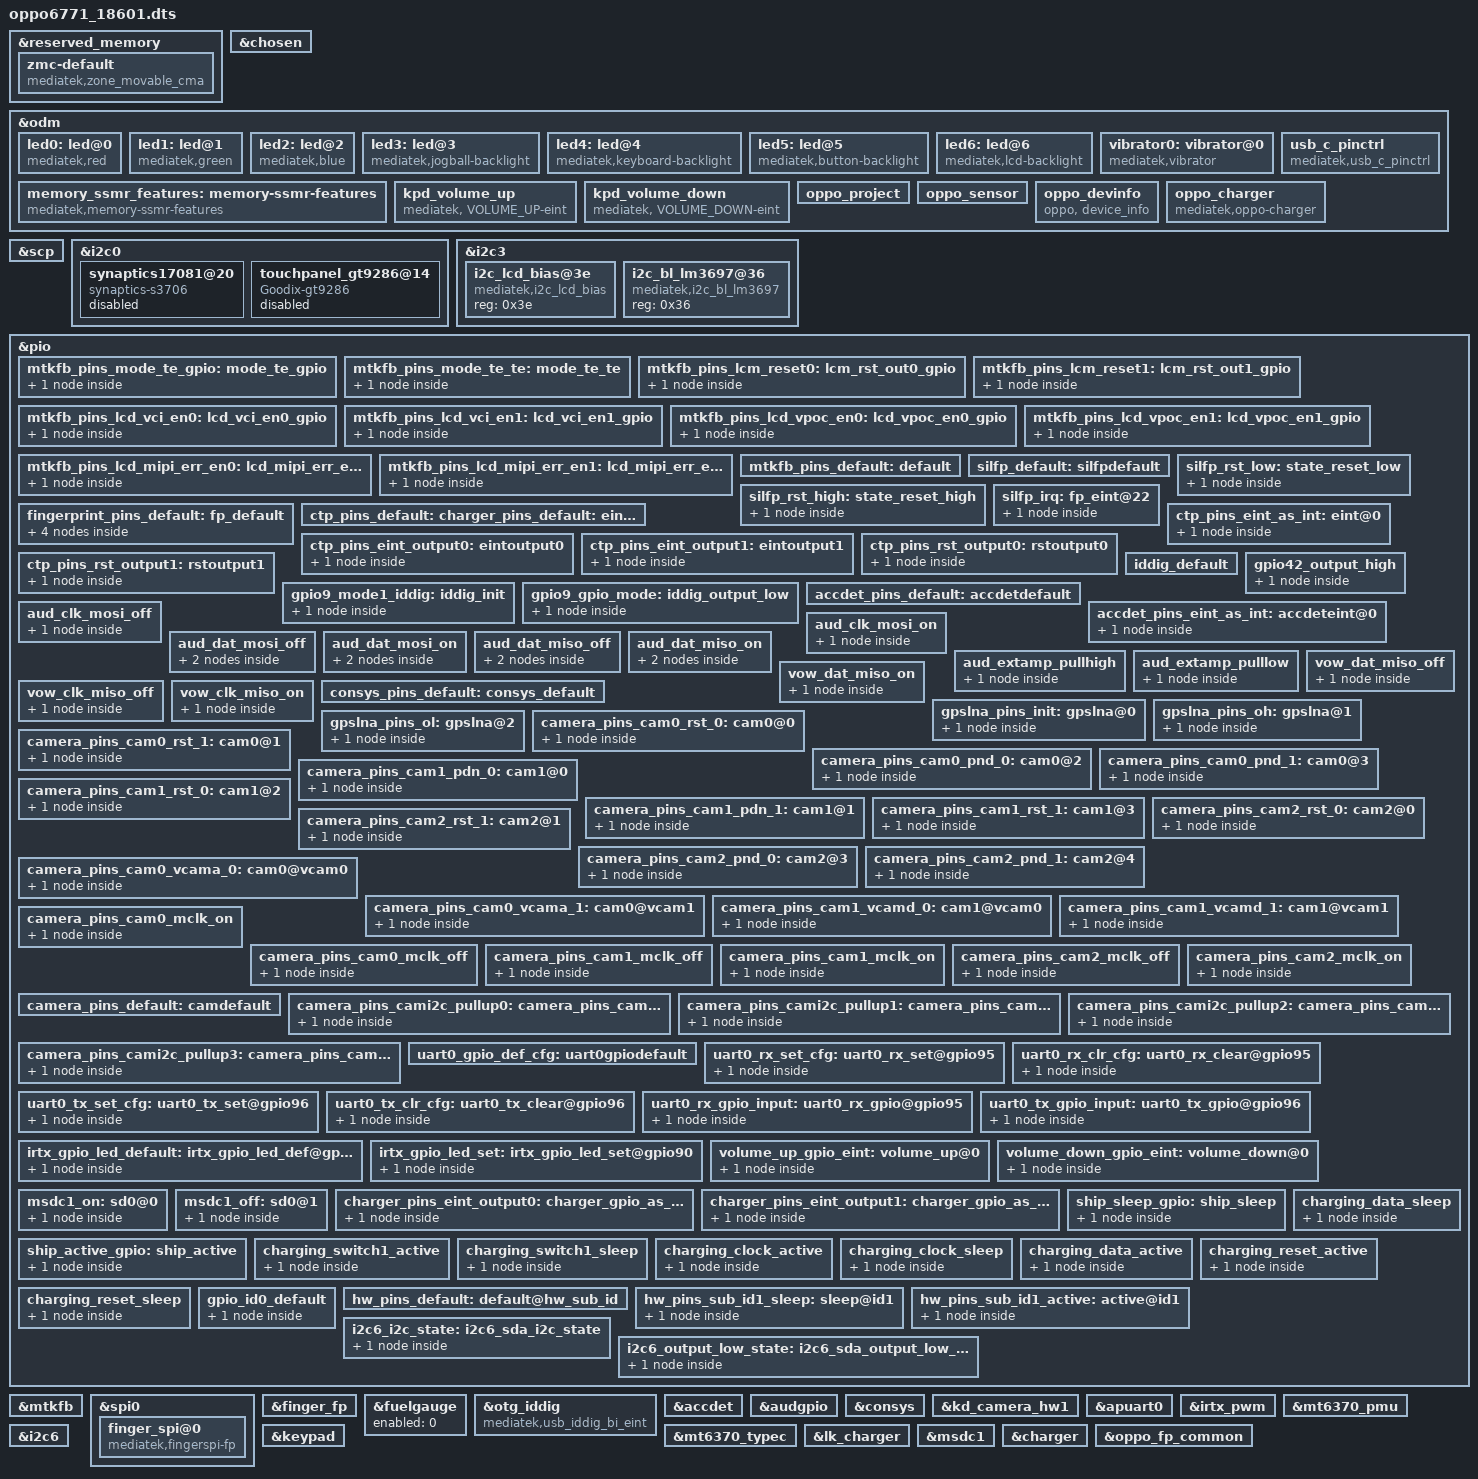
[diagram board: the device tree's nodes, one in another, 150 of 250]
/dts-v1/;
/plugin/;
#include <dt-bindings/interrupt-controller/irq.h>
#include <dt-bindings/interrupt-controller/arm-gic.h>
#include <dt-bindings/pinctrl/mt6771-pinfunc.h>
/* #ifdef ODM_HQ_EDIT */
/* liyan@ODM_HQ.BSP.MMC 2018/10/09 add for T-card irq level */
#include <dt-bindings/mmc/mt6771-msdc.h>
/* #endif */

&reserved_memory {
	#address-cells = <2>;
	#size-cells = <2>;
	ranges;

	zmc-default {
		compatible = "mediatek,zone_movable_cma";
		size = <0 0xffc00000>;
		alignment = <0 0x10000000>;
		alloc-ranges = <1 0x000000000 1 0x00000000>;
	};
};

/* chosen */
&chosen {
	/* fpga may has no lk, we need to specify display info here */
	/* fb buffer is reserved using this dts by memory node above */

	atag,videolfb-fb_base_l = <0x5e605000>;
	atag,videolfb-fb_base_h = <0x0>;
	atag,videolfb-islcmfound = <1>;
	atag,videolfb-islcm_inited = <0>;
	atag,videolfb-fps= <6000>;
	atag,videolfb-vramSize= <0x017bb000>;
	atag,videolfb-lcmname= "nt35595_fhd_dsi_cmd_truly_nt50358_drv";
};

&odm {
	/* liguangxian@ODM.Bsp.Charger  2018/10/11 add for charger battery parameter */
    #include "bat_setting/realme_18601_mt6771_battery_prop_ext.dtsi"
	led0:led@0 {
		compatible = "mediatek,red";
		led_mode = <0>;
		data = <1>;
		pwm_config = <0 0 0 0 0>;
	};
	led1:led@1 {
		compatible = "mediatek,green";
		led_mode = <0>;
		data = <1>;
		pwm_config = <0 0 0 0 0>;
	};
	led2:led@2 {
		compatible = "mediatek,blue";
		led_mode = <0>;
		data = <1>;
		pwm_config = <0 0 0 0 0>;
	};
	led3:led@3 {
		compatible = "mediatek,jogball-backlight";
		led_mode = <0>;
		data = <1>;
		pwm_config = <0 0 0 0 0>;
	};
	led4:led@4 {
		compatible = "mediatek,keyboard-backlight";
		led_mode = <0>;
		data = <1>;
		pwm_config = <0 0 0 0 0>;
	};
	led5:led@5 {
		compatible = "mediatek,button-backlight";
		led_mode = <0>;
		data = <1>;
		pwm_config = <0 0 0 0 0>;
	};
	led6:led@6 {
		compatible = "mediatek,lcd-backlight";
		/* #ifndef VENDOR_EDIT */
		/* LiPing-m@PSW.MM.Display.LCD.Machine, 2017/11/03, Add for porting 17197 lcd driver */
		/* led_mode = <5>; */
		/* #else VENDOR_EDIT */
		/*led_mode = <4>;  */
		/* #endif VENDOR_EDIT */
		//#ifndef ODM_HQ_EDIT
		//liyan@ODM.Multimedia.LCD  2018/10/03 modify for lcd-bl mode
		//led_mode = <5>;
		//#else
		led_mode = <4>;
		//#endif
		data = <1>;
		pwm_config = <0 1 0 0 0>;
	};
	vibrator0:vibrator@0 {
		compatible = "mediatek,vibrator";
//#ifdef VENDOR_EDIT
//Tong.han@Bsp.Group.Tp,2016/12/16, Modify for vibrator enhance even vibra_time below 9ms
		vib_timer = <30>;
		vib_limit = <0>;
//#else
//		vib_timer = <25>;
//		vib_limit = <9>;
//#endif
//#ifndef VENDOR_EDIT
//Fuchun.Liao@BSP.CHG.Basic 2018/01/04 modify vib_vol from 2800mv to 3000mv
		//vib_vol= <9>;
//#else
		vib_vol= <11>;
//#endif /* VENDOR_EDIT */
	};
	memory_ssmr_features: memory-ssmr-features {
		compatible = "mediatek,memory-ssmr-features";
		svp-size = <0 0>;
		iris-recognition-size = <0 0>;
		2d_fr-size = <0 0>;
		tui-size = <0 0>;
		wfd-size = <0 0>;
		prot-sharedmem-size = <0 0>;
	};
	usb_c_pinctrl:usb_c_pinctrl {
		compatible = "mediatek,usb_c_pinctrl";
	};

//#ifdef VENDOR_EDIT
/* Bin.Li@EXP.BSP.bootloader.bootflow, 2017/05/16, Add volume up and down */
	kpd_volume_up:kpd_volume_up {
		compatible = "mediatek, VOLUME_UP-eint";
		interrupt-parent = <&pio>;
		interrupts = <93 IRQ_TYPE_EDGE_FALLING 93 0>;
		debounce = <32000>;
		status = "okay";
	};

	kpd_volume_down:kpd_volume_down {
		compatible = "mediatek, VOLUME_DOWN-eint";
		interrupt-parent = <&pio>;
		interrupts = <94 IRQ_TYPE_EDGE_FALLING 94 0>;
		debounce = <32000>;
		status = "okay";
	};
//#endif


//#ifdef VENDOR_EDIT
/*Bin.Li@EXP.BSP.bootloader.bootflow, 2017/05/15, Add for oppo project */
	oppo_project:oppo_project {
/*Weiguixiong@RM.BSP.bootloader.bootflow,2018/12/14, delete proper for vts*/
/*
		nProject = <0>;
		nModem = <0>;
		nOperator = <0>;
		nPCBVersion = <0>;
*/
	};
//#endif /*VENDOR_EDIT*/

//#ifdef VENDOR_EDIT
/*Fei.Mo@PSW.BSP.Sensor, 2017/12/18, Add for sensor calibration paramaters */
	oppo_sensor:oppo_sensor {
/*Weiguixiong@RM.BSP.bootloader.bootflow,2018/12/14, delete proper for vts*/
/*
		gain_als = <0>;
		prox_offset = <0 0 0 0 0 0>;
		gsensor_sign = <0 0 0>; //1 represent negtive, 0 positive
		gsensor_offset = <0 0 0>;
		gyro_sign = <0 0 0>;//1 represent negtive, 0 positive
		gyro_offset = <0 0 0>;
*/
	};
//#endif /*VENDOR_EDIT*/

//ifdef VENDOR_EDIT
/* Bin.Li@EXP.BSP.bootloader.bootflow, 2017/07/07, Add device-info */
	oppo_devinfo:oppo_devinfo {
		compatible = "oppo, device_info";
	};
//endif

oppo_charger: oppo_charger {
	compatible = "mediatek,oppo-charger";
    pinctrl-names = "default", "charger_gpio_as_output_low", "charger_gpio_as_output_high", "ship_sleep", "ship_active";
	pinctrl-0 = <&charger_pins_default>;
	pinctrl-1 = <&charger_pins_eint_output0>;
	pinctrl-2 = <&charger_pins_eint_output1>;
	pinctrl-3 = <&ship_sleep_gpio>;
	pinctrl-4 = <&ship_active_gpio>;
	qcom,input_current_charger_ma = <2000>;
	qcom,input_current_usb_ma = <500>;
	qcom,input_current_led_ma = <1200>;
	qcom,input_current_led_ma_forcmcc = <500>;
	qcom,input_current_camera_ma = <1200>;
	qcom,input_current_led_ma_high = <1200>;
	qcom,led_high_bat_decidegc = <380>;
	qcom,input_current_led_ma_warm = <1200>;
	qcom,led_warm_bat_decidegc = <350>;
	qcom,input_current_led_ma_normal = <1200>;

	qcom,input_current_calling_ma = <1500>;
	qcom,iterm-disabled = <0>;
	qcom,iterm-ma = <210>;
	qcom,recharge-mv = <100>;
	//qcom,external_gauge;
	qcom,batt_capacity_mah = <4230>;
	qcom,removed_bat_decidegc = <190>;  /* < -19C */
	qcom,cold_bat_decidegc = <30>;  /* -3C ~ 0C */
	qcom,temp_cold_vfloat_mv = <3970>;
	qcom,temp_cold_fastchg_current_ma = <364>;
	qcom,little_cold_bat_decidegc = <0>;	/* 0C ~ 5C */
	qcom,temp_little_cold_vfloat_mv = <4370>;
	qcom,temp_little_cold_fastchg_current_ma = <615>;
	qcom,cool_bat_decidegc = <50>;	/* 5C ~ 12C */
	qcom,temp_cool_vfloat_mv = <4370>;
	qcom,temp_cool_fastchg_current_ma_high = <1125>;
	qcom,temp_cool_fastchg_current_ma_low = <615>;
	qcom,little_cool_bat_decidegc = <120>;	/* 12C ~ 22C */
	qcom,temp_little_cool_vfloat_mv = <4370>;
	qcom,temp_little_cool_fastchg_current_ma = <1945>;
	qcom,normal_bat_decidegc = <220>;	/* 22C ~ 45C */
	qcom,temp_normal_fastchg_current_ma = <2665>;
	qcom,temp_normal_vfloat_mv_normalchg = <4370>;
	qcom,warm_bat_decidegc = <450>;		/* 45C ~ 53C */
	qcom,temp_warm_vfloat_mv = <4080>;
	qcom,temp_warm_fastchg_current_ma = <1125>;
	qcom,hot_bat_decidegc = <530>;
	qcom,non_standard_vfloat_mv = <4000>;
	qcom,non_standard_fastchg_current_ma = <512>;

	qcom,non_standard_vfloat_sw_limit = <3950>;
	qcom,cold_vfloat_sw_limit = <3930>;
	qcom,little_cold_vfloat_sw_limit = <4320>;
	qcom,cool_vfloat_sw_limit = <4320>;
	qcom,little_cool_vfloat_sw_limit = <4320>;
	qcom,normal_vfloat_sw_limit = <4320>;
	qcom,warm_vfloat_sw_limit = <4030>;
	
	qcom,non_standard_vfloat_over_sw_limit = <4000>;
	qcom,cold_vfloat_over_sw_limit = <4000>;
	qcom,little_cold_vfloat_over_sw_limit = <4390>;
	qcom,cool_vfloat_over_sw_limit = <4390>;
	qcom,little_cool_vfloat_over_sw_limit = <4390>;
	qcom,normal_vfloat_over_sw_limit = <4390>;
	qcom,warm_vfloat_over_sw_limit = <4100>;
	qcom,sw_vfloat_over_protect_enable;

	qcom,max_chg_time_sec = <36000>;
	qcom,charger_hv_thr = <5800>;
	qcom,charger_lv_thr = <3400>;
	qcom,vbatt_full_thr = <4400>;
	qcom,vbatt_hv_thr = <4500>;
	qcom,vfloat_step_mv = <16>;
	//qcom,suspend_after_full;
	qcom,check_batt_full_by_sw;
	qcom,chg_ctrl_by_calling;
	qcom,chg_ctrl_by_lcd;
	qcom,chg_ctrl_by_camera;
	/*Qiao.Hu@EXP.BSP.LCD.Machine, 2017/07/20, Add  function for chargerid distinguish*/
	qcom,usb_shell_ctrl;
	qcom,default_iterm_ma = <210>;
	qcom,default_temp_normal_fastchg_current_ma = <2665>;
	qcom,default_normal_vfloat_sw_limit = <4320>;
	qcom,default_temp_normal_vfloat_mv = <4370>;
	qcom,default_normal_vfloat_over_sw_limit = <4390>;
};
};

&scp {
	core_1 = "enable";
	scp_sramSize = <0x00080000>;     /* scp_A_sram_size */
};

//#ifdef VENDOR_EDIT
/*MingQiang.Guo@PSW.BSP.TP,  2018/01/01, Add for TP s3706*/
&i2c0 {
	#address-cells = <1>;
	#size-cells = <0>;

	synaptics17081@20 {
        status = "disable";
	compatible = "synaptics-s3706";
	reg = <0x20>;
	chip-name = "S3706";

	/* Interrupt && Irq-gpio */
	interrupt-parent = <&pio>;
        interrupts = <1 0x2008 1 0>;

	/* Power Config */
	enable2v8_gpio= <&pio 90 0>;
	//vdd_2v8-supply = <&touchpanel_vdd>;
	//vcc_1v8-supply = <&pm660_l14>;

	/* Other HW Resource */
	irq-gpio = <&pio 1 0x2008>;
	reset-gpio =  <&pio 42 0>;
	pinctrl-names = "default";
	//pinctrl-0 = "&ts_int_active &ts_reset_active";

	touchpanel,max-num-support = <10>;
	touchpanel,tx-rx-num = <16 33>;
	touchpanel,panel-coords = <1080 2280>;
	touchpanel,display-coords = <1080 2280>;

	/* SW Support Feature Control */
	black_gesture_support;
	/*Guohua.Zhong@BSP.TP.Function, 2018/01/30, enable edge limit*/
	edge_limit_support;
	//spurious_fingerprint_support;
	/*Guohua.Zhong@BSP.TP.Function, 2018/02/01, enable charger pump*/
	charger_pump_support;
	fw_update_app_support;
	game_switch_support;
	smart_gesture_support;

	/*
	 *Virtual Key Config:
	 *1:touchpanel,button-type: <virtualkey_type  supportted_button-map>
	 *virtualkey_type:
	 *Type 1: using board_properties
	 *Type 2: using same IC (button zone&& touch zone are seprate)
	 *Type 3: using diffrent IC (button zone&& touch zone are seprate)
	 *Type 4: No need of virtual key process
	 *supportted_button-map:select|menu|home|back
	 *
	 *2:touchpanel,button-map
	 *type (X1,Y1)(X2,Y2)(X3,Y3)(Width_X,Hight_Y)--Only when button-type is 0
	 */
	touchpanel,button-type = <4>;
	touchpanel.button-TRx = <0 0>;
    };

     touchpanel_gt9286@14 {
		status = "disable";
         compatible = "Goodix-gt9286";
         reg = <0x14>;
         chip-name = "GT9286";

         interrupt-parent = <&pio>;
         interrupts = <1 0x2002 1 0>;

         //vcc_1v8-supply = <&mt_pmic_vio18_ldo_reg>;
         //vdd_2v8-supply = <&touchpanel_vdd>;

         enable2v8_gpio= <&pio 90 0>;
         irq-gpio = <&pio 1 0x2002>;
         reset-gpio = <&pio 42 0>;

         pinctrl-names = "default";
         //pinctrl-0 = <&tp_irq_pin_default &tp_rst_pin_default &tp_2v8_pin_default>;

         touchpanel,max-num-support = <10>;
         touchpanel,tx-rx-num = <16 33>;
         touchpanel,panel-coords = <1080 2280>;
         touchpanel,display-coords = <1080 2280>;

         register-is-16bit;
         edge_limit_support;
         charger_pump_support;
         fw_update_app_support;
         black_gesture_support;
         //spurious_fingerprint_support;
         //lcd_trigger_fp_check;
         smart_gesture_support;
         esd_handle_support;
         game_switch_support;
		
         /*
         *Virtual Key Config:
         *1:touchpanel,button-type: <virtualkey_type  supportted_button-map>
         *virtualkey_type:
         *Type 1: using board_properties
         *Type 2: using same IC (button zone&& touch zone are seprate)
         *Type 3: using diffrent IC (button zone&& touch zone are seprate)
         *Type 4: No need of virtual key process
         *supportted_button-map:select|menu|home|back
         *
         *2:touchpanel,button-map
         *type (X1,Y1)(X2,Y2)(X3,Y3)(Width_X,Hight_Y)--Only when button-type is 0
         */

         touchpanel,button-type = <4 0x00>;

         /*read goodix cfg group from dts*/
         read_cfg_group_from_dts;
         goodix,gtp_cfg_group = /bits/ 8 <0x12 0x38 0x04 0xE8 0x08 0x3A 0x7D 0x00 0xA8 0xE2 0x0E 0x8C 0x50 0x32 0x50 0x12 0x11 0x0C 
										0x20 0x00 0xFF 0x80 0x82 0xDC 0x4A 0x0F 0x03 0x75 0x1E 0x3C 0x00 0x33 0x00 0x41 0x00 0x00 
										0x14 0x14 0x00 0x40 0x50 0x0C 0x02 0x42 0x48 0x00 0x88 0x68 0x21 0x85 0x87 0xDF 0x07 0x38 
										0x7F 0x80 0x6E 0x53 0x24 0x33 0x03 0x64 0xC8 0xC0 0x4A 0x32 0x32 0x03 0x04 0x8A 0x74 0x85 
										0x85 0x81 0x95 0x80 0xA6 0x7F 0xB7 0x7F 0x42 0x4B 0x40 0x00 0x00 0x00 0x00 0x00 0x00 0x00 
										0x00 0x00 0x00 0x0F 0x1E 0x08 0x00 0x46 0x28 0x00 0x00 0x00 0x00 0x53 0x26 0x0B 0x00 0x35 
										0x01 0x73 0x0A 0x32 0xFC 0x9E 0x8C 0x00 0x00 0x00 0x00 0x00 0x00 0x00 0x00 0x20 0x00 0x00 
										0x00 0x00 0x00 0x00 0x00 0x00 0x00 0xD2 0x27 0x56 0xDF 0x07 0x50 0x32 0x1F 0x1E 0x1B 0x1D 
										0x1C 0x1A 0x19 0x16 0x17 0x14 0x15 0x13 0x12 0x11 0x18 0x0F 0x10 0x0E 0x0D 0x0C 0x0A 0x0B 
										0x08 0x09 0x07 0x06 0x01 0x00 0x02 0x05 0x04 0x03 0x1A 0x18 0x19 0x0A 0x0E 0x0D 0x0C 0x0F 
										0x0B 0x03 0x08 0x09 0x07 0x06 0x04 0x05 0x02 0xFF 0xFF 0xFF 0x6E 0x78 0x00 0x30 0x40 0x83 
										0x00 0x04 0x04 0x63 0xAF 0x1B 0x00 0x00 0x00 0x00 0x00 0x00 0x00 0x33 0x00 0x00 0x96 0x88 
										0x14 0x88 0x74 0x65 0x20 0x14 0x14 0x50 0x6E 0x31 0x05 0x64 0x02 0x44 0x00 0x80 0x1E 0x9D 
										0x09 0x13 0x17 0x43 0x01>;
     };
};
//#endif /* VENDOR_EDIT */
/* #ifdef VENDOR_EDIT */
/* LiPing-m@PSW.MM.Display.LCD.Machine, 2017/11/03, Add for porting 17197 lcd driver */
&i2c3 {
    #address-cells = <1>;
    #size-cells = <0>;

       i2c_lcd_bias@3e {
               compatible = "mediatek,i2c_lcd_bias";
               reg = <0x3e>;
               status = "okay";
       };
       i2c_bl_lm3697@36 {
               compatible = "mediatek,i2c_bl_lm3697";
               reg = <0x36>;
               status = "okay";
       };
};

&pio {

	mtkfb_pins_mode_te_gpio: mode_te_gpio {
		pins_cmd_dat {
			pins = <PINMUX_GPIO44__FUNC_GPIO44>;
	};
		};

	mtkfb_pins_mode_te_te: mode_te_te {
		pins_cmd_dat {
			pins = <PINMUX_GPIO44__FUNC_DSI_TE>;
		};
};

	mtkfb_pins_lcm_reset0: lcm_rst_out0_gpio {
		pins_cmd_dat {
			pins = <PINMUX_GPIO45__FUNC_GPIO45>;
			slew-rate = <1>;
			output-low;
		};
};

	mtkfb_pins_lcm_reset1: lcm_rst_out1_gpio {
		pins_cmd_dat {
			pins = <PINMUX_GPIO45__FUNC_GPIO45>;
			slew-rate = <1>;
			output-high;
		};
};

	mtkfb_pins_lcd_vci_en0: lcd_vci_en0_gpio {
		pins_cmd_dat {
			pins = <PINMUX_GPIO179__FUNC_GPIO179>;
			slew-rate = <1>;
			output-low;
		};
	};

	mtkfb_pins_lcd_vci_en1: lcd_vci_en1_gpio {
		pins_cmd_dat {
			pins = <PINMUX_GPIO179__FUNC_GPIO179>;
			slew-rate = <1>;
			output-high;
		};
	};

	mtkfb_pins_lcd_vpoc_en0: lcd_vpoc_en0_gpio {
		pins_cmd_dat {
			pins = <PINMUX_GPIO25__FUNC_GPIO25>;
			slew-rate = <1>;
			output-low;
		};
	};

	mtkfb_pins_lcd_vpoc_en1: lcd_vpoc_en1_gpio {
		pins_cmd_dat {
			pins = <PINMUX_GPIO25__FUNC_GPIO25>;
			slew-rate = <1>;
			output-high;
		};
	};

	mtkfb_pins_lcd_mipi_err_en0: lcd_mipi_err_en0_gpio {
		pins_cmd_dat {
			pins = <PINMUX_GPIO178__FUNC_GPIO178>;
			slew-rate = <1>;
			output-low;
		};
	};

	mtkfb_pins_lcd_mipi_err_en1: lcd_mipi_err_en1_gpio {
		pins_cmd_dat {
			pins = <PINMUX_GPIO178__FUNC_GPIO178>;
			slew-rate = <1>;
			output-high;
		};
	};

	mtkfb_pins_default: default {
};
};

&mtkfb {
	pinctrl-names = "default", "mode_te_gpio", "mode_te_te", "lcm_rst_out0_gpio",
	"lcm_rst_out1_gpio", "lcd_vci_en0_gpio", "lcd_vci_en1_gpio","lcd_vpoc_en0_gpio",
	"lcd_vpoc_en1_gpio","lcd_mipi_err_en0_gpio", "lcd_mipi_err_en1_gpio";
	pinctrl-0 = <&mtkfb_pins_default>;
	pinctrl-1 = <&mtkfb_pins_mode_te_gpio>;
	pinctrl-2 = <&mtkfb_pins_mode_te_te>;
	pinctrl-3 = <&mtkfb_pins_lcm_reset0>;
	pinctrl-4 = <&mtkfb_pins_lcm_reset1>;
	pinctrl-5 = <&mtkfb_pins_lcd_vci_en0>;
	pinctrl-6 = <&mtkfb_pins_lcd_vci_en1>;
	pinctrl-7 = <&mtkfb_pins_lcd_vpoc_en0>;
	pinctrl-8 = <&mtkfb_pins_lcd_vpoc_en1>;
	pinctrl-9 = <&mtkfb_pins_lcd_mipi_err_en0>;
	pinctrl-10 = <&mtkfb_pins_lcd_mipi_err_en1>;
	status = "okay";
};
/* #endif VENDOR_EDIT */

/* Zhitongze@ODM_HQ.BSP.FINGERPRINT 2018/10/13 add for silead fingerprint driver */
/* FINGERPRINT start */
&spi0 {
		#address-cells = <1>;
		#size-cells = <0>;
       	finger_spi@0 {
		compatible = "mediatek,fingerspi-fp";
        reg = <0>;
		spi-id = <0>;
		spi-irq = <22>;
		spi-reg = <0x1100a000>;
		spi-max-frequency = <8000000>;
		netlink-event = <30>;
		status = "okay";
        };
};
&finger_fp {
	pinctrl-names = "default", "rst-low", "rst-high",
	                "irq-init", "spi-default";
	pinctrl-0 = <&silfp_default>;
	pinctrl-1 = <&silfp_rst_low>;
	pinctrl-2 = <&silfp_rst_high>;
	pinctrl-3 = <&silfp_irq>;
	pinctrl-4 = <&fingerprint_pins_default>;
	status = "okay";
};

&pio {
	silfp_default: silfpdefault {
	};
	silfp_rst_low: state_reset_low {
		pins_cmd_dat {
			pins = <PINMUX_GPIO158__FUNC_GPIO158>;
			slew-rate = <1>;
			output-low;
		};
	};
	silfp_rst_high: state_reset_high {
		pins_cmd_dat {
			pins = <PINMUX_GPIO158__FUNC_GPIO158>;
			slew-rate = <1>;
			output-high;
		};
	};
	silfp_irq: fp_eint@22 {
		pins_cmd_dat {
			pins = <PINMUX_GPIO22__FUNC_GPIO22>;
			slew-rate = <0>;
			bias-disable;
		};
	};
	fingerprint_pins_default: fp_default {
		pins_cmd_dat {
			pins = <PINMUX_GPIO86__FUNC_SPI0_CSB>;
			slew-rate = <1>;
			bias-pull-up;
		};

		pins_cmd2_dat {
			pins = <PINMUX_GPIO88__FUNC_SPI0_CLK>;
			slew-rate = <1>;
			bias-pull-down;
		};

		pins_cmd3_dat {
			pins = <PINMUX_GPIO85__FUNC_SPI0_MI>;
			slew-rate = <0>;
			bias-pull-down;
		};

		pins_cmd4_dat {
			pins = <PINMUX_GPIO87__FUNC_SPI0_MO>;
			slew-rate = <1>;
			bias-pull-down;
		};
	};
};
/* FINGERPRINT end */
/* Zhitongze@ODM_HQ.BSP.FINGERPRINT 2018/10/13 add for silead fingerprint driver */


/* TOUCH start */
/*Weiguixiong@RM.BSP.bootloader.bootflow,2018/12/14, delete proper for vts*/
/*
&touch {
	tpd-resolution = <1080 1920>;
	use-tpd-button = <0>;
	tpd-key-num = <3>;
	tpd-key-local= <139 172 158 0>;
	tpd-key-dim-local = <90 883 100 40 230 883 100 40 370 883 100 40 0 0 0 0>;
	tpd-max-touch-num = <5>;
	tpd-filter-enable = <1>;
	tpd-filter-pixel-density = <146>;
	tpd-filter-custom-prameters = <0 0 0 0 0 0 0 0 0 0 0 0>;
	tpd-filter-custom-speed = <0 0 0>;
	pinctrl-names = "default", "state_eint_as_int", "state_eint_output0", "state_eint_output1",
		"state_rst_output0", "state_rst_output1";
	pinctrl-0 = <&ctp_pins_default>;
	pinctrl-1 = <&ctp_pins_eint_as_int>;
	pinctrl-2 = <&ctp_pins_eint_output0>;
	pinctrl-3 = <&ctp_pins_eint_output1>;
	pinctrl-4 = <&ctp_pins_rst_output0>;
	pinctrl-5 = <&ctp_pins_rst_output1>;
	status = "okay";
};
*/

&pio {
	ctp_pins_default: eint0default {
	};
	ctp_pins_eint_as_int: eint@0 {
		pins_cmd_dat {
			pins = <PINMUX_GPIO1__FUNC_GPIO1>;
			slew-rate = <0>;
			bias-disable;
		};
	};
	ctp_pins_eint_output0: eintoutput0 {
		pins_cmd_dat {
			pins = <PINMUX_GPIO1__FUNC_GPIO1>;
			slew-rate = <1>;
			output-low;
		};
	};
	ctp_pins_eint_output1: eintoutput1 {
		pins_cmd_dat {
			pins = <PINMUX_GPIO1__FUNC_GPIO1>;
			slew-rate = <1>;
			output-high;
		};
	};
	ctp_pins_rst_output0: rstoutput0 {
		pins_cmd_dat {
			pins = <PINMUX_GPIO2__FUNC_GPIO2>;
			slew-rate = <1>;
			output-low;
		};
	};
	ctp_pins_rst_output1: rstoutput1 {
		pins_cmd_dat {
			pins = <PINMUX_GPIO2__FUNC_GPIO2>;
			slew-rate = <1>;
			output-high;
		};
	};
};
/* TOUCH end */
//#ifdef VENDOR_EDIT
//PengNan@BSP.CHG.Basic, 2017/09/07, add for compatabling two fuelgauge.
&fuelgauge{
	enabled = <0>;
};
//#endif
//#ifdef VENDOR_EDIT
/* Qiao.Hu@BSP.BaseDrv.CHG.Basic, 2017/11/19, Add for charging */
// delete for weijun 18601 not support fast charging

//#endif /* VENDOR_EDIT */
/* Qiao.Hu@@Prd6.BaseDrv.USB.Basic, 2017/07/25, Add for otg */
&otg_iddig {
	/* Qiao.Hu@EXP.BSP.CHG.basic, 2017/05/09, Add for otg support */
	compatible = "mediatek,usb_iddig_bi_eint";
	pinctrl-names = "iddig_default", "iddig_init", "iddig_output_low",
			"gpio42_output_high" ;
	pinctrl-0 = <&iddig_default>;
	pinctrl-1 = <&gpio9_mode1_iddig>;
	pinctrl-2 = <&gpio9_gpio_mode>;
	pinctrl-3 = <&gpio42_output_high>;
	status = "okay";
    	/* Qiao.Hu@EXP.BSP.CHG.basic, 2017/05/25, Add for OTG GPIO */
	qcom,otg_switch_gpio = <9>;

};
&pio {
	iddig_default: iddig_default {
	};
	//#ifdef VENDOR_EDIT
	/* Qiao.Hu@EXP.BSP.CHG.basic, 2017/11/28, Add for otg support */
	gpio9_mode1_iddig: iddig_init {
		pins_cmd_dat {
			pins = <PINMUX_GPIO9__FUNC_GPIO9>;
			slew-rate = <0>;
			bias-pull-up = <00>;
		};
	};
	gpio9_gpio_mode: iddig_output_low {
		pins_cmd_dat {
			pins = <PINMUX_GPIO9__FUNC_GPIO9>;
			slew-rate = <1>;
			output-low;
		};
	};

	gpio42_output_high: gpio42_output_high {
		pins_cmd_dat {
			pins = <PINMUX_GPIO42__FUNC_GPIO42>;
			slew-rate = <1>;
			output-high;
		};
	};

	//#endif /* VENDOR_EDIT */
};


/* accdet start */
&accdet {
	/* accdet micbias voltage: 0x07,2.7v;0x05,2.5v;0x02,1.9v */
	//#ifdef VENDOR_EDIT
	//Yongzhi.Zhang@PSW.MM.AudioDriver.Codec, 2018/03/10,
	//modify for changing micbias vol to 2.7V for headset mic
	accdet-mic-vol = <7>;
	//#else /* VENDOR_EDIT */
	//accdet-mic-vol = <6>;
	//#endif /* VENDOR_EDIT */
	headset-mode-setting = <0x500 0x500 1 0x1f0 0x800 0x800 0x20 0x44>;
	accdet-plugout-debounce = <1>;
	/*1:ACC mode, 2:low cost without in bias, 6:low cost with in bias*/
	//#ifdef VENDOR_EDIT
	//Yongzhi.Zhang@PSW.MM.AudioDriver.HeadsetDet, 2017/12/28, Modify for ACC MODE
	accdet-mic-mode = <1>;
	//#else /* VENDOR_EDIT */
	//accdet-mic-mode = <2>;
	//#endif /* VENDOR_EDIT */
	/* eint_level_trigger: 8,LEVEL_LOW(default);4,LEVEL_HIGH;others,LEVEL_LOW */
	headset-eint-level-pol = <8>;
	/*0--MD_MAX--UP_MAX--DW_MAX*/
        //#ifndef VENDOR_EDIT
        /* Tao.Ouyang@RM.MM.AudioDriver.HeadsetDet,1628533, 2018/11/20, Modify for support the volume "-" key of samsung headset */
        //headset-three-key-threshold = <0 82 170 306>;
        //#else /* VENDOR_EDIT */
	headset-three-key-threshold = <0 80 220 400>;
	//#endif /* VENDOR_EDIT */
	headset-three-key-threshold-CDD = <0 121 192 600>;
	/*0--MD_MAX--VOICE_MAX--UP_MAX--DW_MAX*/
	headset-four-key-threshold = <0 58 121 192 400>;
	/*moisture external resister ohm*/
	moisture-external-r = <2000000>;
	/*moisture internal resister ohm*/
	moisture-internal-r = <47000>;
	/*moisture of water resister ohm*/
	moisture-water-r = <10000>;
	/* ACCDET GPIO standardization ACC mode no use */
	pinctrl-names = "default", "state_eint_as_int";
	pinctrl-0 = <&accdet_pins_default>;
	pinctrl-1 = <&accdet_pins_eint_as_int>;
	status = "okay";
};
&pio {
	accdet_pins_default: accdetdefault {
	};
	accdet_pins_eint_as_int: accdeteint@0 {
		pins_cmd_dat {
			/*pins = <PINMUX_GPIO7__FUNC_GPIO7>;*/
			slew-rate = <0>;
			bias-disable;
		};
	};
};
/* accdet end */

/* AUDIO GPIO standardization */
&audgpio {
	pinctrl-names = "aud_clk_mosi_off",
			"aud_clk_mosi_on",
			"aud_dat_mosi_off",
			"aud_dat_mosi_on",
			"aud_dat_miso_off",
			"aud_dat_miso_on",
			"extamp-pullhigh",
			"extamp-pulllow",
			"vow_dat_miso_off",
			"vow_dat_miso_on",
			"vow_clk_miso_off",
			"vow_clk_miso_on";
	pinctrl-0 = <&aud_clk_mosi_off>;
	pinctrl-1 = <&aud_clk_mosi_on>;
	pinctrl-2 = <&aud_dat_mosi_off>;
	pinctrl-3 = <&aud_dat_mosi_on>;
	pinctrl-4 = <&aud_dat_miso_off>;
	pinctrl-5 = <&aud_dat_miso_on>;
	pinctrl-6 = <&aud_extamp_pullhigh>;
	pinctrl-7 = <&aud_extamp_pulllow>;
	pinctrl-8 = <&vow_dat_miso_off>;
	pinctrl-9 = <&vow_dat_miso_on>;
	pinctrl-10 = <&vow_clk_miso_off>;
	pinctrl-11 = <&vow_clk_miso_on>;
	status = "okay";
};

&pio {
	aud_clk_mosi_off: aud_clk_mosi_off {
		pins_cmd0_dat {
			pins = <PINMUX_GPIO136__FUNC_GPIO136>;
		};
	};

	aud_clk_mosi_on: aud_clk_mosi_on {
		pins_cmd0_dat {
			pins = <PINMUX_GPIO136__FUNC_AUD_CLK_MOSI>;
		};
	};

	aud_dat_mosi_off: aud_dat_mosi_off {
		pins_cmd1_dat {
			pins = <PINMUX_GPIO138__FUNC_GPIO138>;
		};
		pins_cmd2_dat {
			pins = <PINMUX_GPIO139__FUNC_GPIO139>;
		};
	};

	aud_dat_mosi_on: aud_dat_mosi_on {
		pins_cmd1_dat {
			pins = <PINMUX_GPIO138__FUNC_AUD_DAT_MOSI0>;
		};
		pins_cmd2_dat {
			pins = <PINMUX_GPIO139__FUNC_AUD_DAT_MOSI1>;
		};
	};

	aud_dat_miso_off: aud_dat_miso_off {
		pins_cmd1_dat {
			pins = <PINMUX_GPIO142__FUNC_GPIO142>;
		};
		pins_cmd2_dat {
			pins = <PINMUX_GPIO143__FUNC_GPIO143>;
		};
	};

	aud_dat_miso_on: aud_dat_miso_on {
		pins_cmd1_dat {
			pins = <PINMUX_GPIO142__FUNC_AUD_DAT_MISO0>;
		};
		pins_cmd2_dat {
			pins = <PINMUX_GPIO143__FUNC_AUD_DAT_MISO1>;
		};
	};

	//#ifdef ODM_HQ_EDIT
	/*fanxiongnan_hq@ODM.Multimedia.Audio 2018/10/09 modified for speaker bringup*/
	aud_extamp_pullhigh: aud_extamp_pullhigh {
		pins_cmd_dat {
			pinmux = <PINMUX_GPIO165__FUNC_GPIO165>;
			slew-rate = <1>;
			output-high;
		};
	};

	aud_extamp_pulllow: aud_extamp_pulllow {
		pins_cmd_dat {
			pinmux = <PINMUX_GPIO165__FUNC_GPIO165>;
			slew-rate = <1>;
			output-low;
		};
	};

	vow_dat_miso_off: vow_dat_miso_off {
		pins_cmd1_dat {
			pins = <PINMUX_GPIO142__FUNC_GPIO142>;
		};
	};

	vow_dat_miso_on: vow_dat_miso_on {
		pins_cmd1_dat {
			pins = <PINMUX_GPIO142__FUNC_VOW_DAT_MISO>;
		};
	};

	vow_clk_miso_off: vow_clk_miso_off {
		pins_cmd3_dat {
			pins = <PINMUX_GPIO143__FUNC_GPIO143>;
		};
	};

	vow_clk_miso_on: vow_clk_miso_on {
		pins_cmd3_dat {
			pins = <PINMUX_GPIO143__FUNC_VOW_CLK_MISO>;
		};
	};
};
/* AUDIO end */

/* CONSYS GPIO standardization */
&pio {
	consys_pins_default: consys_default {
	};
	gpslna_pins_init: gpslna@0 {
		pins_cmd_dat {
			pins = <PINMUX_GPIO92__FUNC_GPIO92>;
			slew-rate = <1>;
			output-low;
			bias-disable;
		};
	};
	gpslna_pins_oh: gpslna@1 {
		pins_cmd_dat {
			pins = <PINMUX_GPIO92__FUNC_GPIO92>;
			slew-rate = <1>;
			output-high;
		};
	};
	gpslna_pins_ol: gpslna@2 {
		pins_cmd_dat {
			pins = <PINMUX_GPIO92__FUNC_GPIO92>;
			slew-rate = <1>;
			output-low;
		};
	};
};
&consys {
	pinctrl-names = "default", "gps_lna_state_init", "gps_lna_state_oh", "gps_lna_state_ol";
	pinctrl-0 = <&consys_pins_default>;
	pinctrl-1 = <&gpslna_pins_init>;
	pinctrl-2 = <&gpslna_pins_oh>;
	pinctrl-3 = <&gpslna_pins_ol>;
	status = "okay";
};
/* CONSYS end */
/* CAMERA GPIO standardization */
&pio {
	camera_pins_cam0_rst_0: cam0@0 {
		pins_cmd_dat {
			pins = <PINMUX_GPIO101__FUNC_GPIO101>;
			slew-rate = <1>; /*direction 0:in, 1:out*/
			output-low;/*direction out used only. output_low or high*/
		};
	};
	camera_pins_cam0_rst_1: cam0@1 {
		pins_cmd_dat {
			pins = <PINMUX_GPIO101__FUNC_GPIO101>;
			slew-rate = <1>;
			output-high;
		};
	};
	camera_pins_cam0_pnd_0: cam0@2 {
		pins_cmd_dat {
			pins = <PINMUX_GPIO97__FUNC_GPIO97>;
			slew-rate = <1>;
			output-low;
		};
	};
	camera_pins_cam0_pnd_1: cam0@3 {
		pins_cmd_dat {
			pins = <PINMUX_GPIO97__FUNC_GPIO97>;
			slew-rate = <1>;
			output-high;
		};
	};
	/* config ldo strength for front dvdd*/
	camera_pins_cam1_pdn_0: cam1@0 {
		pins_cmd_dat {
			pins = <PINMUX_GPIO98__FUNC_GPIO98>;
			slew-rate = <1>; /*direction 0:in, 1:out*/
			output-low;/*direction out used only. output_low or high*/
		};
	};
	camera_pins_cam1_pdn_1: cam1@1 {
		pins_cmd_dat {
			pins = <PINMUX_GPIO98__FUNC_GPIO98>;
			slew-rate = <1>;
			output-high;
		};
	};
	camera_pins_cam1_rst_0: cam1@2 {
		pins_cmd_dat {
			pins = <PINMUX_GPIO102__FUNC_GPIO102>;
			slew-rate = <1>; /*direction 0:in, 1:out*/
			output-low;/*direction out used only. output_low or high*/
		};
	};
	camera_pins_cam1_rst_1: cam1@3 {
		pins_cmd_dat {
			pins = <PINMUX_GPIO102__FUNC_GPIO102>;
			slew-rate = <1>;
			output-high;
		};
	};
	camera_pins_cam2_rst_0: cam2@0 {
		pins_cmd_dat {
			pins = <PINMUX_GPIO109__FUNC_GPIO109>;
			slew-rate = <1>;
			output-low;
		};
	};
	camera_pins_cam2_rst_1: cam2@1 {
		pins_cmd_dat {
			pins = <PINMUX_GPIO109__FUNC_GPIO109>;
			slew-rate = <1>;
			output-high;
		};
	};
	camera_pins_cam2_pnd_0: cam2@3 {
		pins_cmd_dat {
			pins = <PINMUX_GPIO107__FUNC_GPIO107>;
			slew-rate = <1>;
			output-low;
		};
	};
	camera_pins_cam2_pnd_1: cam2@4 {
		pins_cmd_dat {
			pins = <PINMUX_GPIO107__FUNC_GPIO107>;
			slew-rate = <1>;
			output-high;
		};
	};
/*main avdd*/
	camera_pins_cam0_vcama_0: cam0@vcam0 {
		pins_cmd_dat {
			pins = <PINMUX_GPIO177__FUNC_GPIO177>;
			slew-rate = <1>;
			output-low;
		};
	};
	camera_pins_cam0_vcama_1: cam0@vcam1 {
		pins_cmd_dat {
			pins = <PINMUX_GPIO177__FUNC_GPIO177>;
			slew-rate = <1>;
			output-high;
		};
	};

/*sub dvdd*/
	camera_pins_cam1_vcamd_0: cam1@vcam0 {
		pins_cmd_dat {
			pins = <PINMUX_GPIO169__FUNC_GPIO169>;
			slew-rate = <1>;
			output-low;
		};
	};

	camera_pins_cam1_vcamd_1: cam1@vcam1 {
		pins_cmd_dat {
			pins = <PINMUX_GPIO169__FUNC_GPIO169>;
			slew-rate = <1>;
			output-high;
		};
	};
//#ifdef ODM_HQ_EDIT
/*chen.li @ Camera.Drv modify for delete oppo main2 camera config 201801017*/
/*	camera_pins_cam2_vcamd_0: cam2@vcamd0 {
		pins_cmd_dat {
			pins = <PINMUX_GPIO26__FUNC_GPIO26>;
			slew-rate = <1>;
			output-low;
		};
	};
	camera_pins_cam2_vcamd_1: cam2@vcamd1 {
		pins_cmd_dat {
			pins = <PINMUX_GPIO26__FUNC_GPIO26>;
			slew-rate = <1>;
			output-high;
		};
	};*/
//#endif /* end of ODM_HQ_EDIT */

	camera_pins_cam0_mclk_on: camera_pins_cam0_mclk_on {
		pins_cmd_dat {
			pins = <PINMUX_GPIO99__FUNC_CMMCLK0>;
		};
	};
	camera_pins_cam0_mclk_off: camera_pins_cam0_mclk_off {
		pins_cmd_dat {
			pins = <PINMUX_GPIO99__FUNC_GPIO99>;
		};
	};
	camera_pins_cam1_mclk_off: camera_pins_cam1_mclk_off {
		pins_cmd_dat {
			pins = <PINMUX_GPIO100__FUNC_GPIO100>;
		};
	};
	camera_pins_cam1_mclk_on: camera_pins_cam1_mclk_on {
		pins_cmd_dat {
			pins = <PINMUX_GPIO100__FUNC_CMMCLK1>;
		};
	};
	camera_pins_cam2_mclk_off: camera_pins_cam2_mclk_off {
		pins_cmd_dat {
			pins = <PINMUX_GPIO108__FUNC_GPIO108>;
		};
	};
	camera_pins_cam2_mclk_on: camera_pins_cam2_mclk_on {
		pins_cmd_dat {
			pins = <PINMUX_GPIO108__FUNC_CMMCLK2>;
		};
	};
	camera_pins_default: camdefault {
	};
	//#ifdef VENDOR_EDIT
	/*Zezhi.Wang@Camera.Driver add for 18601 for camera i2c pullup disable after DVT board 20181128*/
	camera_pins_cami2c_pullup0: camera_pins_cami2c_pullup@0 {
		pins_cmd_dat {
			pins = <PINMUX_GPIO103__FUNC_SCL2>;
			slew-rate = <0>;
			bias-disable;
		};
	};
	camera_pins_cami2c_pullup1: camera_pins_cami2c_pullup@1 {
		pins_cmd_dat {
			pins = <PINMUX_GPIO104__FUNC_SDA2>;
			slew-rate = <0>;
			bias-disable;
		};
	};
	camera_pins_cami2c_pullup2: camera_pins_cami2c_pullup@2 {
		pins_cmd_dat {
			pins = <PINMUX_GPIO105__FUNC_SCL4>;
			slew-rate = <0>;
			bias-disable;
		};
	};
	camera_pins_cami2c_pullup3: camera_pins_cami2c_pullup@3 {
		pins_cmd_dat {
			pins = <PINMUX_GPIO106__FUNC_SDA4>;
			slew-rate = <0>;
			bias-disable;
		};
	};
	//#endif
};
&kd_camera_hw1 {
	pinctrl-names = "default",
			"cam0_rst0",
			"cam0_rst1",
			"cam0_pnd0",
			"cam0_pnd1",
			"cam1_pnd0",
			"cam1_pnd1",
			"cam1_rst0",
			"cam1_rst1",
			"cam2_rst0",
			"cam2_rst1",
			"cam2_pnd0",
			"cam2_pnd1",
			"cam_ldo_vcama_0",
			"cam_ldo_vcama_1",
			"cam_ldo_sub_vcamd_0",
			"cam_ldo_sub_vcamd_1",
			"cam0_mclk_off",
			"cam0_mclk_on",
			"cam1_mclk_off",
			"cam1_mclk_on",
			"cam2_mclk_off",
			"cam2_mclk_on",
			//#ifdef VENDOR_EDIT
			/*Zezhi.Wang@Camera.Driver add for 18601 camera i2c pullup disable after DVT board 20181128*/
			"cami2c_pullup0",
			"cami2c_pullup1",
			"cami2c_pullup2",
			"cami2c_pullup3";
			//#endif

	pinctrl-0 = <&camera_pins_default>;
	pinctrl-1 = <&camera_pins_cam0_rst_0>;
	pinctrl-2 = <&camera_pins_cam0_rst_1>;
	pinctrl-3 = <&camera_pins_cam0_pnd_0>;
	pinctrl-4 = <&camera_pins_cam0_pnd_1>;
	pinctrl-5 = <&camera_pins_cam1_pdn_0>; /* for front dvdd power strength*/
	pinctrl-6 = <&camera_pins_cam1_pdn_1>;
	pinctrl-7 = <&camera_pins_cam1_rst_0>;
	pinctrl-8 = <&camera_pins_cam1_rst_1>;
	pinctrl-9 = <&camera_pins_cam2_rst_0>;
	pinctrl-10 = <&camera_pins_cam2_rst_1>;
	pinctrl-11 = <&camera_pins_cam2_pnd_0>;
	pinctrl-12 = <&camera_pins_cam2_pnd_1>;
	pinctrl-13 = <&camera_pins_cam0_vcama_0>;
	pinctrl-14 = <&camera_pins_cam0_vcama_1>;
	pinctrl-15 = <&camera_pins_cam1_vcamd_0>;
	pinctrl-16 = <&camera_pins_cam1_vcamd_1>;
	pinctrl-17 = <&camera_pins_cam0_mclk_off>;
	pinctrl-18 = <&camera_pins_cam0_mclk_on>;
	pinctrl-19 = <&camera_pins_cam1_mclk_off>;
	pinctrl-20 = <&camera_pins_cam1_mclk_on>;
	pinctrl-21 = <&camera_pins_cam2_mclk_off>;
	pinctrl-22 = <&camera_pins_cam2_mclk_on>;
	//#ifdef VENDOR_EDIT
	/*Zezhi.Wang@Camera.Driver add for 18601 camera i2c pullup disable after DVT board 20181128*/
	pinctrl-23 = <&camera_pins_cami2c_pullup0>;
	pinctrl-24 = <&camera_pins_cami2c_pullup1>;
	pinctrl-25 = <&camera_pins_cami2c_pullup2>;
	pinctrl-26 = <&camera_pins_cami2c_pullup3>;
	//#endif

	status = "okay";
};
/* UART GPIO */
&apuart0 {
	pinctrl-names = "uart0_gpio_default",
			"uart0_rx_set",
			"uart0_rx_clear",
			"uart0_tx_set",
			"uart0_tx_clear",
//#ifdef VENDOR_EDIT
//Jianchao.Shi@PSW.BSP.CHG.Basic, 2018/10/11, sjc Add for chargerid
			"uart0_rx_gpio",
			"uart0_tx_gpio";
//#endif /*VENDOR_EDIT*/
	pinctrl-0 = <&uart0_gpio_def_cfg>;
	pinctrl-1 = <&uart0_rx_set_cfg>;
	pinctrl-2 = <&uart0_rx_clr_cfg>;
	pinctrl-3 = <&uart0_tx_set_cfg>;
	pinctrl-4 = <&uart0_tx_clr_cfg>;
//#ifdef VENDOR_EDIT
//Jianchao.Shi@PSW.BSP.CHG.Basic, 2018/10/11, sjc Add for chargerid
	pinctrl-5 = <&uart0_rx_gpio_input>;
	pinctrl-6 = <&uart0_tx_gpio_input>;
//#endif /*VENDOR_EDIT*/
	status = "okay";
};

&pio {
	/* UART GPIO Settings - Start */
	/* UART0: rx set, rx clear, tx clear, tx clear*/
	uart0_gpio_def_cfg:uart0gpiodefault {

	};
	uart0_rx_set_cfg:uart0_rx_set@gpio95 {
		pins_cmd_dat {
			pins = <PINMUX_GPIO95__FUNC_URXD0>;
		};
	};
	uart0_rx_clr_cfg:uart0_rx_clear@gpio95 {
		pins_cmd_dat {
			pins = <PINMUX_GPIO95__FUNC_GPIO95>;
			slew-rate = <1>;
			output-high;
		};
	};
	uart0_tx_set_cfg:uart0_tx_set@gpio96 {
		pins_cmd_dat {
			pins = <PINMUX_GPIO96__FUNC_UTXD0>;
		};
	};
	uart0_tx_clr_cfg:uart0_tx_clear@gpio96 {
		pins_cmd_dat {
			pins = <PINMUX_GPIO96__FUNC_GPIO96>;
			slew-rate = <1>;
			output-high;
		};
	};
	//#ifdef VENDOR_EDIT
	//Jianchao.Shi@PSW.BSP.CHG.Basic, 2018/10/11, sjc Add for chargerid
	uart0_rx_gpio_input:uart0_rx_gpio@gpio95 {
		pins_cmd_dat {
			pins = <PINMUX_GPIO95__FUNC_GPIO95>;
			input-enable;
			slew-rate = <0>;
			bias-disable;
		};
	};
	uart0_tx_gpio_input:uart0_tx_gpio@gpio96 {
		pins_cmd_dat {
			pins = <PINMUX_GPIO96__FUNC_GPIO96>;
			input-enable;
			slew-rate = <0>;
			bias-disable;
		};
	};
	//#endif /*VENDOR_EDIT*/
};/* UART GPIO end */

/* IRTX GPIO Start */
&irtx_pwm {
	pinctrl-names = "irtx_gpio_led_default", "irtx_gpio_led_set";
	pinctrl-0 = <&irtx_gpio_led_default>;
	pinctrl-1 = <&irtx_gpio_led_set>;
	status = "okay";
};
&pio {
	/* IRTX GPIO Settings -Start */
	/* default: GPIO0, output, high */
	irtx_gpio_led_default:irtx_gpio_led_def@gpio90 {
		pins_cmd_dat {
			pins = <PINMUX_GPIO90__FUNC_GPIO90>;
			slew-rate = <1>;
			bias-disable;
			output-low;
			input-schmitt-enable = <0>;
		};
	};

	irtx_gpio_led_set:irtx_gpio_led_set@gpio90 {
		pins_cmd_dat {
			pins = <PINMUX_GPIO90__FUNC_PWM_A>;
			slew-rate = <1>;
			output-high;
		};
	};
}; /* IRTX GPIO Settings -End */

&mt6370_pmu {
	mt6370,intr_gpio_num = <10>; /* direct defined GPIO num */
	mt6370,intr_gpio = <&pio 10 0x0>;
};

&mt6370_typec {
	mt6370pd,intr_gpio_num = <41>; /* direct defined GPIO num */
	mt6370pd,intr_gpio = <&pio 41 0x0>;
};

/* USB TYPEC GPIO start */
//#ifndef VENDOR_EDIT /* Jianchao.Shi@BSP.CHG.Basic, 2018/09/20, sjc Delete for OTG */
/*&pio {
	usb_default: usb_default {
	};

	gpio_redriver_c1_init: c1_init {
		pins_cmd_dat {
			pins = <PINMUX_GPIO18__FUNC_GPIO18>;
			slew-rate = <1>;
			output-low;
		};
	};

	gpio_redriver_c1_low: c1_low {
		pins_cmd_dat {
			pins = <PINMUX_GPIO18__FUNC_GPIO18>;
			slew-rate = <1>;
			output-low;
		};
	};

	gpio_redriver_c1_hiz: c1_highz {
		pins_cmd_dat {
			pins = <PINMUX_GPIO18__FUNC_GPIO18>;
			slew-rate= <0>;
			bias-disable;
		};
	};

	gpio_redriver_c1_high: c1_high {
		pins_cmd_dat {
			pins = <PINMUX_GPIO18__FUNC_GPIO18>;
			slew-rate = <1>;
			output-high;
		};
	};

	gpio_redriver_c2_init: c2_init {
		pins_cmd_dat {
			pins = <PINMUX_GPIO17__FUNC_GPIO17>;
			slew-rate = <1>;
			output-low;
		};
	};

	gpio_redriver_c2_low: c2_low {
		pins_cmd_dat {
			pins = <PINMUX_GPIO17__FUNC_GPIO17>;
			slew-rate = <1>;
			output-low;
		};
	};

	gpio_redriver_c2_hiz: c2_highz {
		pins_cmd_dat {
			pins = <PINMUX_GPIO17__FUNC_GPIO17>;
			slew-rate= <0>;
			bias-disable;
		};
	};

	gpio_redriver_c2_high: c2_high {
		pins_cmd_dat {
			pins = <PINMUX_GPIO17__FUNC_GPIO17>;
			slew-rate = <1>;
			output-high;
		};
	};

	gpio_u3_switch_sel1: u3_sw_sel1 {
		pins_cmd_dat {
			pins = <PINMUX_GPIO177__FUNC_GPIO177>;
			slew-rate = <1>;
			output-low;
		};
	};

	gpio_u3_switch_sel2: u3_sw_sel2 {
		pins_cmd_dat {
			pins = <PINMUX_GPIO177__FUNC_GPIO177>;
			slew-rate = <1>;
			output-high;
		};
	};

	gpio_u3_switch_enable: u3_sw_en {
	};

	gpio_u3_switch_disable: u3_sw_dis {
	};
};

&usb_c_pinctrl {
	pinctrl-names = "usb_default",
		"redriver_c1_init",
		"redriver_c1_low",
		"redriver_c1_hiz",
		"redriver_c1_high",
		"redriver_c2_init",
		"redriver_c2_low",
		"redriver_c2_hiz",
		"redriver_c2_high",
		"u3_switch_sel1",
		"u3_switch_sel2",
		"u3_switch_enable",
		"u3_switch_disable";

	pinctrl-0 = <&usb_default>;
	pinctrl-1 = <&gpio_redriver_c1_init>;
	pinctrl-2 = <&gpio_redriver_c1_low>;
	pinctrl-3 = <&gpio_redriver_c1_hiz>;
	pinctrl-4 = <&gpio_redriver_c1_high>;
	pinctrl-5 = <&gpio_redriver_c2_init>;
	pinctrl-6 = <&gpio_redriver_c2_low>;
	pinctrl-7 = <&gpio_redriver_c2_hiz>;
	pinctrl-8 = <&gpio_redriver_c2_high>;
	pinctrl-9 = <&gpio_u3_switch_sel1>;
	pinctrl-10 = <&gpio_u3_switch_sel2>;
	pinctrl-11 = <&gpio_u3_switch_enable>;
	pinctrl-12 = <&gpio_u3_switch_disable>;
	status = "okay";
*/
//	usb_switch-data {
//		en_pin_num = <0>;
//		en_pin_val = <0>; /*DISABLE=0 ENABLE=1*/
//		sel_pin_num = <177>;
//		sel_pin_val = <1>; /*CC1=1, CC2=2*/
//		c1_pin_num = <18>;
//		c1_pin_val = <2>; /*Low=0, HighZ=1, High=2*/
//		c2_pin_num = <17>;
//		c2_pin_val = <1>;
//	};
//};
//#endif /*VENDOR_EDIT*/
/* USB TYPEC GPIO end */

//#ifdef VENDOR_EDIT
/* Bin.Li@EXP.BSP.bootloader.bootflow, 2017/05/16, Add volume up and down */
&keypad {
	keypad,volume-up	= <&pio 93 0x00>;
	keypad,volume-down	= <&pio 94 0x00>;
	pinctrl-names = "volume_up_as_int", "volume_down_as_int";
	pinctrl-0 = <&volume_up_gpio_eint>;
	pinctrl-1 = <&volume_down_gpio_eint>;
	status = "okay";
};

&pio {
	volume_up_gpio_eint:volume_up@0{
		pins_cmd_dat {
			pins = <PINMUX_GPIO93__FUNC_GPIO93>;
			slew-rate = <0>;  /*direction 0:in, 1:out*/
			bias-pull-up = <00>;
			input-enable;
		};
	};
	volume_down_gpio_eint:volume_down@0{
		pins_cmd_dat {
			pins = <PINMUX_GPIO94__FUNC_GPIO94>;
			slew-rate = <0>;  /*direction 0:in, 1:out*/
			bias-pull-up = <00>;
			input-enable;
		};
	};
};

//#endif /*VENDOR_EDIT*/

/* USB TYPEC GPIO end */
/* #ifdef ODM_HQ_EDIT */
&lk_charger {
	chg1_ta_ac_charger_current = <2000000>;
	chg2_ta_ac_charger_current = <2000000>;
};

//#ifdef VENDOR_EDIT
/* Bin.Li@EXP.BSP.bootloader.bootflow, 2017/05/15, Add for T-card ldo */
&msdc1{
	pinctrl-names = "msdc1_on","msdc1_off";
	pinctrl-0 = <&msdc1_on>;
	pinctrl-1 = <&msdc1_off>;
	status = "okay";
};
&pio {
	msdc1_on:sd0@0{
		pins_cmd_dat {
			pins = <PINMUX_GPIO90__FUNC_GPIO90>;
			slew-rate = <1>;
			output-high;
		};
    };
	msdc1_off: sd0@1 {
		pins_cmd_dat {
			pins = <PINMUX_GPIO90__FUNC_GPIO90>;
			slew-rate = <1>;
			output-low;
		};
	};
};
//#endif /*VENDOR_EDIT*/
&charger {
	algorithm_name = "SwitchCharging";
	chg1_ta_ac_charger_current = <2000000>;
	chg2_ta_ac_charger_current = <2000000>;
};
&pio {
	charger_pins_default: eint0default {
	};
	charger_pins_eint_output0: charger_gpio_as_output_low {
		pins_cmd_dat {
			pins = <PINMUX_GPIO151__FUNC_GPIO151>;
			slew-rate = <1>;
			output-low;
		};
	};
	charger_pins_eint_output1: charger_gpio_as_output_high {
		pins_cmd_dat {
			pins = <PINMUX_GPIO151__FUNC_GPIO151>;
			slew-rate = <1>;
			output-high;
		};
	};

	ship_sleep_gpio: ship_sleep {
		pins_cmd_dat {
			pins = <PINMUX_GPIO152__FUNC_GPIO152>;
			slew-rate = <1>;
			output-low;
		};
	};
	ship_active_gpio: ship_active {
		pins_cmd_dat {
			pins = <PINMUX_GPIO152__FUNC_GPIO152>;
			slew-rate = <1>;
			output-high;
		};
	};
};

//#ifdef VENDOR_EDIT
//Fuchun.Liao@BSP.CHG.Basic 2017/11/18 modify for use bq24190 charger
/* #endif */
// delete for weijun 18601 not support fast charging
//#endif /* VENDOR_EDIT */

&pio {
	charging_switch1_active: charging_switch1_active {
		pins_cmd_dat {
			pins = <PINMUX_GPIO166__FUNC_GPIO166>;
			slew-rate = <1>;
			output-high;
		};
	};
	charging_switch1_sleep: charging_switch1_sleep {
		pins_cmd_dat {
			pins = <PINMUX_GPIO166__FUNC_GPIO166>;
			slew-rate = <1>;
			output-low;
		};
	};
	charging_clock_active: charging_clock_active {
		pins_cmd_dat {
			pins = <PINMUX_GPIO10__FUNC_GPIO10>;
			slew-rate = <0>;
			bias-pull-up = <00>;
		};
	};
	charging_clock_sleep: charging_clock_sleep {
		pins_cmd_dat {
			pins = <PINMUX_GPIO10__FUNC_GPIO10>;
			slew-rate = <0>;
			bias-pull-down = <00>;
		};
	};
	charging_data_active: charging_data_active {
		pins_cmd_dat {
			pins = <PINMUX_GPIO10__FUNC_GPIO10>;
			slew-rate = <0>;
			bias-pull-up = <00>;
		};
	};
	charging_data_sleep: charging_data_sleep {
		pins_cmd_dat {
			pins = <PINMUX_GPIO10__FUNC_GPIO10>;
			slew-rate = <0>;
			bias-pull-down = <00>;
		};
	};
	charging_reset_active: charging_reset_active {
		pins_cmd_dat {
			pins = <PINMUX_GPIO160__FUNC_GPIO160>;
			slew-rate = <1>;
			output-high;
		};
	};
	charging_reset_sleep: charging_reset_sleep {
		pins_cmd_dat {
			pins = <PINMUX_GPIO160__FUNC_GPIO160>;
			slew-rate = <1>;
			output-low;
		};
	};
};




/* liyan@ODM_HQ.BSP.MMC 2018/10/09 add for T-card irq level */
&msdc1 {
	cd_level = /bits/ 8 <MSDC_CD_HIGH>;
};
/* #endif */

//ifdef VENDOR_EDIT
/* Qingwen.Liu@PSW.BSP.Fingerprint.Basic, 2018/10/17, Add for EGIS driver baseon trustonic tee */
/*the id config to project dts.*/
&pio{
	gpio_id0_default: gpio_id0_default {
		pins_cmd_dat {
			pins = <PINMUX_GPIO166__FUNC_GPIO166>;
			slew-rate = <0>;
			bias-pull-up = <00>;
			input-enable;
		};
	};
};

&oppo_fp_common {
	oppo,fp-id0 = <&pio 166 0x00>;
	pinctrl-names = "default";
	pinctrl-0 = <&gpio_id0_default>;
};
//#endif/*VENDOR_EDIT*/

//ifdef VENDOR_EDIT
/* Bin.Li@EXP.BSP.bootloader.bootflow, 2017/07/07, Add device-info */
&oppo_devinfo {
        Hw,sub_hwid_1 = <&pio 56 0x00>;
        pinctrl-names = "default", "hw_sub_id_sleep", "hw_sub_id_active";
        pinctrl-0 = <&hw_pins_default>;
        pinctrl-1 = <&hw_pins_sub_id1_sleep>;
        pinctrl-2 = <&hw_pins_sub_id1_active>;
};

&pio {
        hw_pins_default:default@hw_sub_id {
        };

        hw_pins_sub_id1_sleep:sleep@id1 {
                pins_cmd_dat {
                        pins = <PINMUX_GPIO56__FUNC_GPIO56>;
                        slew-rate = <0>;
                        bias-pull-down = <00>;
                        input-enable;
                };
        };

        hw_pins_sub_id1_active:active@id1 {
                pins_cmd_dat {
                        pins = <PINMUX_GPIO56__FUNC_GPIO56>;
                        slew-rate = <0>;
                        bias-pull-up = <00>;
                        input-enable;
                };
        };
};
//endif

//Fuchun.Liao@BSP.CHG.Basic 2017/11/24 modify for oppo dws
#include <oppo6771_18601/cust.dtsi>
//#endif /* VENDOR_EDIT */
/*End of this file, DO NOT ADD ANYTHING HERE*/

//#ifdef VENDOR_EDIT
//tongfeng.huang@BSP.CHG.Basic, 2018/2/27 Add for i2c-6 reset, patch:REQ30000477623
&i2c6 {
       pinctrl-names = "i2c-state", "output-low-state";

       pinctrl-0 = <&i2c6_i2c_state>;
       pinctrl-1 = <&i2c6_output_low_state>;
};
&pio {
       i2c6_i2c_state: i2c6_sda_i2c_state {
                pins_cmd_dat {
                          pins = <PINMUX_GPIO12__FUNC_SDA6>;
                          slew-rate = <0>;
                          bias-disable;
                };
       };
       i2c6_output_low_state: i2c6_sda_output_low_state {
                pins_cmd_dat {
                          pins = <PINMUX_GPIO12__FUNC_GPIO12>;
                          slew-rate = <1>;
                          output-low;
                };
       };
};
//#endif /*VENDOR_EDIT*/

